VERSION "HIPBNYYYYYYYYYYYYYYYYYYYYYYYYYYYYYYYYYYYYY/4/%%%/4/'%**4YYY///"

NS_ :

BS_:

BU_: WaveSculptor22

BO_ 1024 IDInfo: 8 WaveSculptor22
 SG_ TritiumID : 0|32@1+ (1,0) [0|0] "" Vector__XXX
 SG_ SerialNumber : 32|32@1+ (1,0) [0|0] "" Vector__XXX

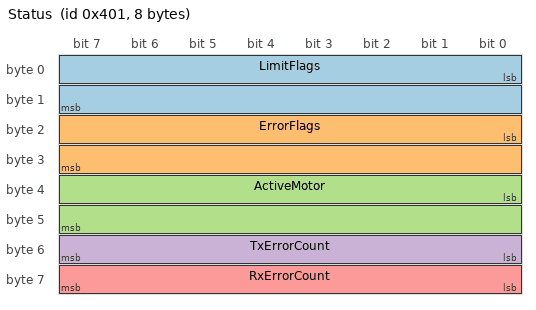
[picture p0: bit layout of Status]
BO_ 1025 Status: 8 WaveSculptor22
 SG_ LimitFlags : 0|16@1+ (1,0) [0|0] "" Vector__XXX
 SG_ ErrorFlags : 16|16@1+ (1,0) [0|0] "" Vector__XXX
 SG_ ActiveMotor : 32|16@1+ (1,0) [0|0] "" Vector__XXX
 SG_ TxErrorCount : 48|8@1+ (1,0) [0|0] "" Vector__XXX
 SG_ RxErrorCount : 56|8@1+ (1,0) [0|0] "" Vector__XXX

BO_ 1026 BusMeasurement: 8 WaveSculptor22
 SG_ BusVoltage : 0|32@1- (1,0) [0|0] "V" Vector__XXX
 SG_ BusCurrent : 32|32@1- (1,0) [0|0] "A" Vector__XXX

BO_ 1027 VelocityMeasurement: 8 WaveSculptor22
 SG_ MotorVelocity : 0|32@1- (1,0) [0|0] "rpm" Vector__XXX
 SG_ VehicleVelocity : 32|32@1- (1,0) [0|0] "m/s" Vector__XXX

BO_ 1028 PhaseCurrentMeasurement: 8 WaveSculptor22
 SG_ PhaseCurrentB : 0|32@1- (1,0) [0|0] "A_rms" Vector__XXX
 SG_ PhaseCurrentC : 32|32@1- (1,0) [0|0] "A_rms" Vector__XXX

BO_ 1029 MotorVoltageVectorMeasurement: 8 WaveSculptor22
 SG_ Vq : 0|32@1- (1,0) [0|0] "V" Vector__XXX
 SG_ Vd : 32|32@1- (1,0) [0|0] "V" Vector__XXX

BO_ 1030 MotorCurrentVectorMeasurement: 8 WaveSculptor22
 SG_ Iq : 0|32@1- (1,0) [0|0] "A" Vector__XXX
 SG_ Id : 32|32@1- (1,0) [0|0] "A" Vector__XXX

BO_ 1031 MotorBackEMFMeasurementPrediction: 8 WaveSculptor22
 SG_ BEMFq : 0|32@1- (1,0) [0|0] "V" Vector__XXX
 SG_ BEMFd : 32|32@1- (1,0) [0|0] "V" Vector__XXX

BO_ 1032 VoltageRail15VMeasurement: 8 WaveSculptor22
 SG_ Supply15V : 32|32@1- (1,0) [0|0] "V" Vector__XXX
 SG_ ReservedSupply15V : 0|32@1- (1,0) [0|0] "" Vector__XXX

BO_ 1033 VoltageRail3V31V9Measurement: 8 WaveSculptor22
 SG_ Supply1V9 : 0|32@1- (1,0) [0|0] "V" Vector__XXX
 SG_ Supply3V3 : 32|32@1- (1,0) [0|0] "V" Vector__XXX

BO_ 1034 Reserved0A: 8 WaveSculptor22
 SG_ Reserved0A0 : 0|32@1- (1,0) [0|0] "" Vector__XXX
 SG_ Reserved0A1 : 32|32@1- (1,0) [0|0] "" Vector__XXX

BO_ 1035 HeatsinkMotorTempMeasurement: 8 WaveSculptor22
 SG_ MotorTemp : 0|32@1- (1,0) [0|0] "C" Vector__XXX
 SG_ HeatsinkTemp : 32|32@1- (1,0) [0|0] "C" Vector__XXX

BO_ 1036 DspBoardTempMeasurement: 8 WaveSculptor22
 SG_ DspBoardTemp : 0|32@1- (1,0) [0|0] "C" Vector__XXX
 SG_ ReservedDspBoardTemp : 32|32@1- (1,0) [0|0] "" Vector__XXX

BO_ 1037 Reserved0D: 8 WaveSculptor22
 SG_ Reserved0D0 : 0|32@1- (1,0) [0|0] "" Vector__XXX
 SG_ Reserved0D1 : 32|32@1- (1,0) [0|0] "" Vector__XXX

BO_ 1038 OdometerBusAhMeasurement: 8 WaveSculptor22
 SG_ Odometer : 0|32@1- (1,0) [0|0] "m" Vector__XXX
 SG_ DCBusAh : 32|32@1- (1,0) [0|0] "Ah" Vector__XXX

BO_ 1047 SlipSpeedMeasurement: 8 WaveSculptor22
 SG_ SlipSpeed : 32|32@1- (1,0) [0|0] "Hz" Vector__XXX
 SG_ ReservedSlipSpeed : 0|32@1- (1,0) [0|0] "" Vector__XXX

CM_ SG_ 1024 TritiumID "Device identifier. 0x00004003";
CM_ SG_ 1024 SerialNumber "Device serial number, allocated at manufacture.";
CM_ SG_ 1025 LimitFlags "Flags indicate which control loop is limiting the output current of the motor controller.";
CM_ SG_ 1025 ErrorFlags "Flags indicate errors.";
CM_ SG_ 1025 ActiveMotor "The index of the active motor currently being used.";
CM_ SG_ 1025 TxErrorCount "The DSP CAN transmission error counter (CAN 2.0)";
CM_ SG_ 1025 RxErrorCount "The DSP CAN receive error counter (CAN 2.0)";
CM_ SG_ 1026 BusVoltage "DC bus voltage at the controller.";
CM_ SG_ 1026 BusCurrent "Current drawn from the DC bus by the controller.";
CM_ SG_ 1027 MotorVelocity "Motor angular frequency in revolutions per minute.";
CM_ SG_ 1027 VehicleVelocity "Vehicle velocity in metres / second.";
CM_ SG_ 1028 PhaseCurrentB "RMS current in motor Phase B.";
CM_ SG_ 1028 PhaseCurrentC "RMS current in motor Phase C.";
CM_ SG_ 1029 Vq "Imaginary component of the applied non-rotating voltage vector to the motor.";
CM_ SG_ 1029 Vd "Real component of the applied non-rotating voltage vector to the motor.";
CM_ SG_ 1030 Iq "Imaginary component of the applied non-rotating current vector to the motor. This current produces torque in the motor and should be in phase with the back-EMF of the motor";
CM_ SG_ 1030 Id "Real component of the applied non-rotating current vector to the motor. This vector represents the field current of the motor.";
CM_ SG_ 1031 BEMFq "The peak of the phase to neutral motor voltage.";
CM_ SG_ 1031 BEMFd "By definition this value is always 0V.";
CM_ SG_ 1032 Supply15V "Actual voltage level of the 15V power rail.";
CM_ SG_ 1033 Supply1V9 "Actual voltage level of the 1.9V DSP power rail.";
CM_ SG_ 1033 Supply3V3 "Actual voltage level of the 3.3V power rail.";
CM_ SG_ 1035 MotorTemp "Internal temperature of the motor";
CM_ SG_ 1035 HeatsinkTemp "Internal temperature of Heat-sink (case).";
CM_ SG_ 1036 DspBoardTemp "Temperature of the DSP board.";
CM_ SG_ 1038 Odometer "Distance the vehicle has travelled since reset.";
CM_ SG_ 1038 DCBusAh "Charge flow into the controller DC bus from the time of reset.";
CM_ SG_ 1047 SlipSpeed "Slip speed when driving an induction motor.";
BA_DEF_ BO_  "GenMsgCycleTime" INT 2 50000;
BA_DEF_ BU_  "GenNodAutoGenSnd" ENUM  "No","Yes";
BA_DEF_ BU_  "GenNodAutoGenDsp" ENUM  "No","Yes";
BA_DEF_  "GenEnvVarEndingDsp" STRING ;
BA_DEF_  "GenEnvVarEndingSnd" STRING ;
BA_DEF_  "GenEnvVarPrefix" STRING ;
BA_DEF_DEF_  "GenMsgCycleTime" 100;
BA_DEF_DEF_  "GenNodAutoGenSnd" "Yes";
BA_DEF_DEF_  "GenNodAutoGenDsp" "Yes";
BA_DEF_DEF_  "GenEnvVarEndingDsp" "Dsp";
BA_DEF_DEF_  "GenEnvVarEndingSnd" "Snd";
BA_DEF_DEF_  "GenEnvVarPrefix" "Env";
BA_ "GenMsgCycleTime" BO_ 1024 1000;
BA_ "GenMsgCycleTime" BO_ 1025 200;
BA_ "GenMsgCycleTime" BO_ 1026 200;
BA_ "GenMsgCycleTime" BO_ 1027 200;
BA_ "GenMsgCycleTime" BO_ 1028 200;
BA_ "GenMsgCycleTime" BO_ 1029 200;
BA_ "GenMsgCycleTime" BO_ 1030 200;
BA_ "GenMsgCycleTime" BO_ 1031 200;
BA_ "GenMsgCycleTime" BO_ 1032 1000;
BA_ "GenMsgCycleTime" BO_ 1033 1000;
BA_ "GenMsgCycleTime" BO_ 1034 0;
BA_ "GenMsgCycleTime" BO_ 1035 1000;
BA_ "GenMsgCycleTime" BO_ 1036 1000;
BA_ "GenMsgCycleTime" BO_ 1037 1000;
BA_ "GenMsgCycleTime" BO_ 1038 1000;
BA_ "GenMsgCycleTime" BO_ 1047 200;
SIG_VALTYPE_ 1026 BusVoltage : 1;
SIG_VALTYPE_ 1026 BusCurrent : 1;
SIG_VALTYPE_ 1027 MotorVelocity : 1;
SIG_VALTYPE_ 1027 VehicleVelocity : 1;
SIG_VALTYPE_ 1028 PhaseCurrentB : 1;
SIG_VALTYPE_ 1028 PhaseCurrentC : 1;
SIG_VALTYPE_ 1029 Vq : 1;
SIG_VALTYPE_ 1029 Vd : 1;
SIG_VALTYPE_ 1030 Iq : 1;
SIG_VALTYPE_ 1030 Id : 1;
SIG_VALTYPE_ 1031 BEMFq : 1;
SIG_VALTYPE_ 1031 BEMFd : 1;
SIG_VALTYPE_ 1032 Supply15V : 1;
SIG_VALTYPE_ 1032 ReservedSupply15V : 1;
SIG_VALTYPE_ 1033 Supply1V9 : 1;
SIG_VALTYPE_ 1033 Supply3V3 : 1;
SIG_VALTYPE_ 1034 Reserved0A0 : 1;
SIG_VALTYPE_ 1034 Reserved0A1 : 1;
SIG_VALTYPE_ 1035 MotorTemp : 1;
SIG_VALTYPE_ 1035 HeatsinkTemp : 1;
SIG_VALTYPE_ 1036 DspBoardTemp : 1;
SIG_VALTYPE_ 1036 ReservedDspBoardTemp : 1;
SIG_VALTYPE_ 1037 Reserved0D0 : 1;
SIG_VALTYPE_ 1037 Reserved0D1 : 1;
SIG_VALTYPE_ 1038 Odometer : 1;
SIG_VALTYPE_ 1038 DCBusAh : 1;
SIG_VALTYPE_ 1047 SlipSpeed : 1;
SIG_VALTYPE_ 1047 ReservedSlipSpeed : 1;
